# CY8C4245AXI_473 register map
File version: 0.1
PSoC 4200
Registers are 32-bit, read-write, no defined reset value unless marked. A register's access mark holds for its fields unless they carry their own. Offsets are from the block's base; lines under a group give offsets from that group; [hi:lo] are bit positions; {n}, {i} and the like mark numbered series; 'fields as' and 'values as' point back to an identical list; <NAME> marks a mode.

## Memory map
0x00000000 EncoderDirection
0x00000000 PWM_1
0x00000000 Timer_BRMS
0x00000000 Index_Counter_1
0x00000000 SPI_1 — Serial Communication Block
0x00000000 I2C — Serial Communication Block
0x00000000 Counter_1

## EncoderDirection
Base 0x00000000
0x400F0071 EncoderDirection_CONTROL_REG 8-bit

## PWM_1
Base 0x00000000
0x40050188 COUNTER — Current counter value
0x4005018C CC — Compare / capture value
0x40050190 CC_BUF — Compare / capture buffer value
0x40050194 PERIOD — Period value
0x40050198 PERIOD_BUF — Period buffer value

## Timer_BRMS
Base 0x00000000
0x40050108 COUNTER — Current counter value
0x4005010C CC — Compare / capture value
0x40050110 CC_BUF — Compare / capture buffer value
0x40050114 PERIOD — Period value
0x40050118 PERIOD_BUF — Period buffer value

## Index_Counter_1
Base 0x00000000
0x400F0003 Index_Counter_1_COUNTER 8-bit — UDB.A0 - Current Counter Value
0x400F0023 Index_Counter_1_PERIOD 8-bit — UDB.D0 - Assigned Period
0x400F0033 Index_Counter_1_COMPARE 8-bit — UDB.D1 - Assigned Compare Value
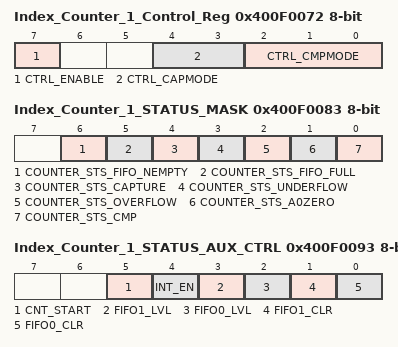
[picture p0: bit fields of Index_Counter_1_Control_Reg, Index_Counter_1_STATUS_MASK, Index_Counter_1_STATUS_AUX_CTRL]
0x400F0072 Index_Counter_1_Control_Reg 8-bit — UDB Control Register - Assigned Control Register Value
  [7] CTRL_ENABLE — Enable Counter
  [4:3] CTRL_CAPMODE — Capture mode
  [2:0] CTRL_CMPMODE — Compare mode
0x400F0083 Index_Counter_1_STATUS_MASK 8-bit — UDB Status bits Interrupt Mask Enable Register
  [6] COUNTER_STS_FIFO_NEMPTY — FIFO Not Empty Status
  [5] COUNTER_STS_FIFO_FULL — FIFO Full Status
  [4] COUNTER_STS_CAPTURE — Capture Status
  [3] COUNTER_STS_UNDERFLOW — Underflow status
  [2] COUNTER_STS_OVERFLOW — Overflow status
  [1] COUNTER_STS_A0ZERO — A0 Zero ouput status
  [0] COUNTER_STS_CMP — Compare output status
0x400F0093 Index_Counter_1_STATUS_AUX_CTRL 8-bit — UDB Auxilliary Control Register
  [5] CNT_START — FIFO0 clear
    0=E_CNT_START0 (Disable counter); 1=E_CNT_START1 (Enable counter)
  [4] INT_EN
    0=E_INT_EN0 (Interrupt disabled); 1=E_INT_EN1 (Interrupt enabled)
  [3] FIFO1_LVL — FIFO level
    0=E_FIFO_LVL_0 (FIFO LVL: input mode: FIFO not full; output mode: FIFO not empty); 1=E_FIFO_LVL_1 (FIFO LVL: input mode: FIFO at least 1/2 empty; output mode: FIFO at least 1/2 full)
  [2] FIFO0_LVL — FIFO level
    values as FIFO1_LVL
  [1] FIFO1_CLR — FIFO1 clear
    0=E_FIFO_CLR_0 (Normal FIFO operation); 1=E_FIFO_CLR_1 (Clear FIFO state)
  [0] FIFO0_CLR — FIFO0 clear
    values as FIFO1_CLR

## Counter_1
Base 0x00000000
0x400F0000 Counter_1_COUNTER 24-bit — UDB.A0 - Current Counter Value
0x400F0020 Counter_1_PERIOD 24-bit — UDB.D0 - Assigned Period
0x400F0030 Counter_1_COMPARE 24-bit — UDB.D1 - Assigned Compare Value
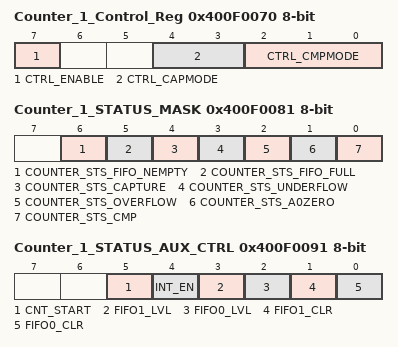
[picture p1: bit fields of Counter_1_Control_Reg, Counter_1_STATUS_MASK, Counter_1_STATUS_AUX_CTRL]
0x400F0070 Counter_1_Control_Reg 8-bit — UDB Control Register - Assigned Control Register Value
  [7] CTRL_ENABLE — Enable Counter
  [4:3] CTRL_CAPMODE — Capture mode
  [2:0] CTRL_CMPMODE — Compare mode
0x400F0081 Counter_1_STATUS_MASK 8-bit — UDB Status bits Interrupt Mask Enable Register
  [6] COUNTER_STS_FIFO_NEMPTY — FIFO Not Empty Status
  [5] COUNTER_STS_FIFO_FULL — FIFO Full Status
  [4] COUNTER_STS_CAPTURE — Capture Status
  [3] COUNTER_STS_UNDERFLOW — Underflow status
  [2] COUNTER_STS_OVERFLOW — Overflow status
  [1] COUNTER_STS_A0ZERO — A0 Zero ouput status
  [0] COUNTER_STS_CMP — Compare output status
0x400F0091 Counter_1_STATUS_AUX_CTRL 8-bit — UDB Auxilliary Control Register
  [5] CNT_START — FIFO0 clear
    0=E_CNT_START0 (Disable counter); 1=E_CNT_START1 (Enable counter)
  [4] INT_EN
    0=E_INT_EN0 (Interrupt disabled); 1=E_INT_EN1 (Interrupt enabled)
  [3] FIFO1_LVL — FIFO level
    0=E_FIFO_LVL_0 (FIFO LVL: input mode: FIFO not full; output mode: FIFO not empty); 1=E_FIFO_LVL_1 (FIFO LVL: input mode: FIFO at least 1/2 empty; output mode: FIFO at least 1/2 full)
  [2] FIFO0_LVL — FIFO level
    values as FIFO1_LVL
  [1] FIFO1_CLR — FIFO1 clear
    0=E_FIFO_CLR_0 (Normal FIFO operation); 1=E_FIFO_CLR_1 (Clear FIFO state)
  [0] FIFO0_CLR — FIFO0 clear
    values as FIFO1_CLR
